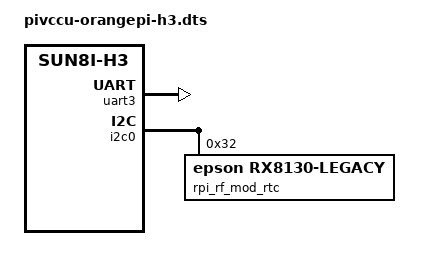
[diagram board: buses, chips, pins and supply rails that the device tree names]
/dts-v1/;
/plugin/;

/ {
  compatible = "allwinner,sun8i-h3";

  fragment@0 {
    target = <&uart3>;
    __overlay__ {
      pinctrl-names = "default";
      pinctrl-0 = <&uart3_pins>;
      status = "okay";
      compatible = "pivccu,dw_apb";
      pivccu,reset-gpios = <&pio 3 14 0>, <&pio 0 10 0>;
      pivccu,led-gpios = <&pio 6 9 0>, <&pio 6 6 0>, <&pio 6 7 0>;
      pivccu,rtc = <&rpi_rf_mod_rtc>;
    };
  };


  fragment@1 {
    target = <&i2c0>;
    __overlay__ {
      #address-cells = <1>;
      #size-cells = <0>;
      status = "okay";

      rpi_rf_mod_rtc: rx8130@32 {
        compatible = "epson,rx8130-legacy";
        reg = <0x32>;
        status = "okay";
        aux-voltage-chargeable = <1>;
        enable-external-capacitor;
      };
    };
  };
};

